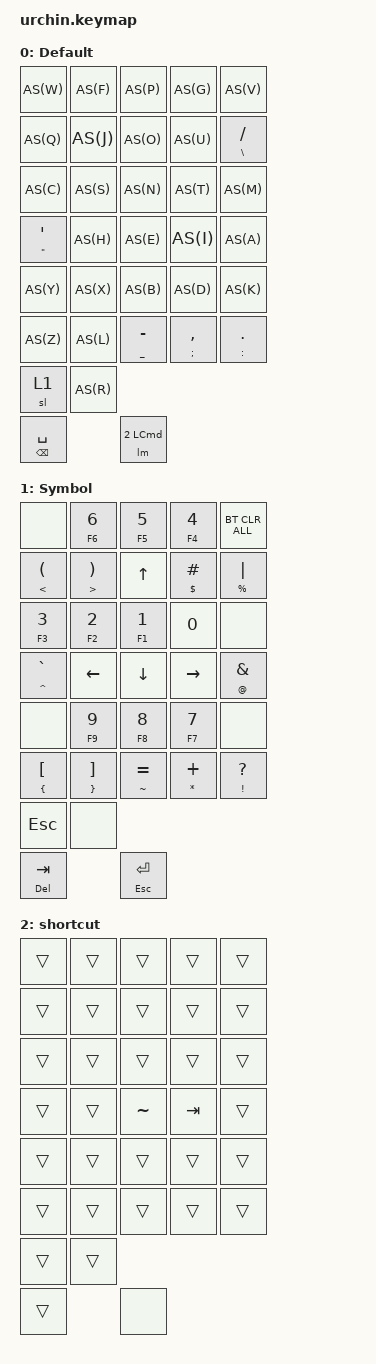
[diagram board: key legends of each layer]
#include <behaviors.dtsi>
#include <dt-bindings/zmk/keys.h>
#include <dt-bindings/zmk/bt.h>

#define AS(keycode) &as LS(keycode) keycode

/ {
	behaviors {
        as: auto_shift {
            compatible = "zmk,behavior-hold-tap";
            #binding-cells = <2>;
            tapping_term_ms = <200>;
            flavor = "tap-preferred";
            bindings = <&kp>, <&kp>;
        };

		lm: layer_modifier {
		    compatible = "zmk,behavior-macro-two-param";
		    wait-ms = <0>;
		    tap-ms = <0>;
		    #binding-cells = <2>;
		    bindings
		        = <&macro_param_1to1>
		        , <&macro_press &mo MACRO_PLACEHOLDER>
		        , <&macro_param_2to1>
		        , <&macro_press &kp MACRO_PLACEHOLDER>
		        , <&macro_pause_for_release>
		        , <&macro_param_2to1>
		        , <&macro_release &kp MACRO_PLACEHOLDER>
		        , <&macro_param_1to1>
		        , <&macro_release &mo MACRO_PLACEHOLDER>
		        ;
		};
    };

	keymap {
		compatible = "zmk,keymap";

		default {
			label = "Default";
			bindings = <
				AS(W) AS(F) AS(P) AS(G) AS(V)
				AS(Q) AS(J) AS(O) AS(U) &as BSLH FSLH

				AS(C) AS(S) AS(N) AS(T) AS(M)
				&as DQT SQT AS(H) AS(E) AS(I) AS(A)
			
				AS(Y) AS(X) AS(B) AS(D) AS(K)
				AS(Z) AS(L) &as UNDER MINUS &as SEMI COMMA &as COLON DOT

				&sl 1 AS(R)
				&as BSPC SPACE &lm 2 LCMD
			>;
		};

		symbol {
			label = "Symbol";
			bindings = <
				&none &as F6 N6 &as F5 N5 &as F4 N4 &bt BT_CLR_ALL
				&as LT LPAR &as GT RPAR &kp UP &as DOLLAR HASH &as PERCENT PIPE

				&as F3 N3 &as F2 N2 &as F1 N1 &kp N0 &none
				&as CARET GRAVE &kp LEFT &kp DOWN &kp RIGHT &as AT AMPS

				&none &as F9 N9 &as F8 N8 &as F7 N7 &none
				&as LBRC LBKT &as RBRC RBKT &as TILDE EQUAL &as STAR PLUS &as EXCL QMARK

				&kp ESC &none
				&as DEL TAB &as ESC RET
			>;
		};

		shortcut {
			label = "shortcut";
			bindings = <
				&trans &trans &trans &trans &trans
				&trans &trans &trans &trans &trans

				&trans &trans &trans &trans &trans
				&trans &trans &kp TILDE &kp TAB &trans

				&trans &trans &trans &trans &trans
				&trans &trans &trans &trans &trans

				&trans &trans
				&trans &none
			>;
		};

	};
};
